# KD32F328CB register map
File version: 1.0
Registers are 32-bit, read-write, reset 0x0 unless marked. A register's access mark holds for its fields unless they carry their own. Offsets are from the block's base; [hi:lo] are bit positions; {n}, {i} and the like mark numbered series.

## Flash
Base 0x40022000
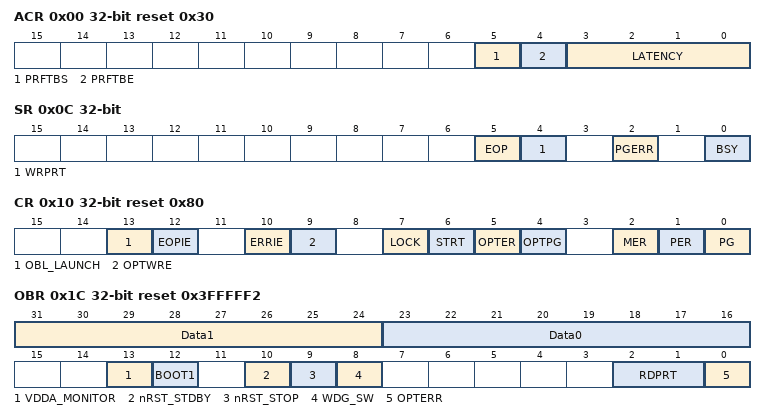
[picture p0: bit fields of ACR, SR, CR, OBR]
0x00 ACR access per field reset 0x30 — Flash access control register
  [5] PRFTBS ro, [4] PRFTBE rw, [3:0] LATENCY rw
0x04 KEYR wo — Flash key register
  [31:0] FKEYR — Flash Key
0x08 OPTKEYR wo — Flash option key register
  [31:0] OPTKEYR — Option byte key
0x0C SR access per field — Flash status register
  [5] EOP rw — End of operation
  [4] WRPRT rw — Write protection error
  [2] PGERR rw — Programming error
  [0] BSY ro — Busy
0x10 CR reset 0x80 — Flash control register
  [13] OBL_LAUNCH — Force option byte loading
  [12] EOPIE — End of operation interrupt enable
  [10] ERRIE — Error interrupt enable
  [9] OPTWRE — Option bytes write enable
  [7] LOCK
  [6] STRT — Start
  [5] OPTER — Option byte erase
  [4] OPTPG — Option byte programming
  [2] MER — Mass erase
  [1] PER — Page erase
  [0] PG — Programming
0x14 AR wo — Flash address register
  [31:0] FAR — Flash address
0x1C OBR ro reset 0x3FFFFF2 — Option byte register
  [31:24] Data1
  [23:16] Data0
  [13] VDDA_MONITOR
  [12] BOOT1
  [10] nRST_STDBY
  [9] nRST_STOP
  [8] WDG_SW
  [2:1] RDPRT — Level protection status
  [0] OPTERR — Option byte error
0x20 WRPR ro reset 0xFFFFFFFF — Write protection register
  [31:0] WRP — Write protect

## OP — operational support
Base 0x40010030
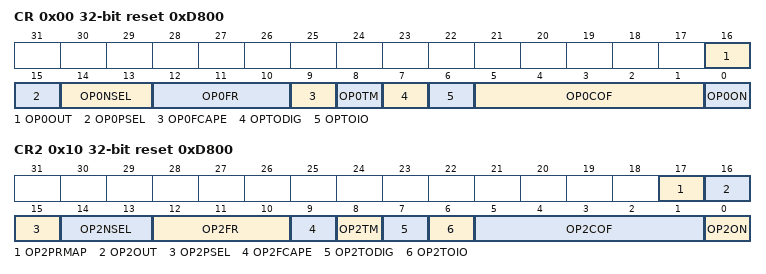
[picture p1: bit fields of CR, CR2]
0x00 CR reset 0xD800
  [16] OP0OUT — Revision Identifier
  [15] OP0PSEL — Revision Identifier
  [14:13] OP0NSEL — Revision Identifier
  [12:10] OP0FR — Revision Identifier
  [9] OP0FCAPE — Revision Identifier
  [8] OP0TM — Revision Identifier
  [7] OPTODIG — Revision Identifier
  [6] OPTOIO — Revision Identifier
  [5:1] OP0COF — Division Identifier
  [0] OP0ON — Device Identifier
0x10 CR2 reset 0xD800
  [17] OP2PRMAP — Revision Identifier
  [16] OP2OUT — Revision Identifier
  [15] OP2PSEL — Revision Identifier
  [14:13] OP2NSEL — Revision Identifier
  [12:10] OP2FR — Revision Identifier
  [9] OP2FCAPE — Revision Identifier
  [8] OP2TM — Revision Identifier
  [7] OP2TODIG — Revision Identifier
  [6] OP2TOIO — Revision Identifier
  [5:1] OP2COF — Division Identifier
  [0] OP2ON — Device Identifier

## DEBUG — Debug support
Base 0x40015800
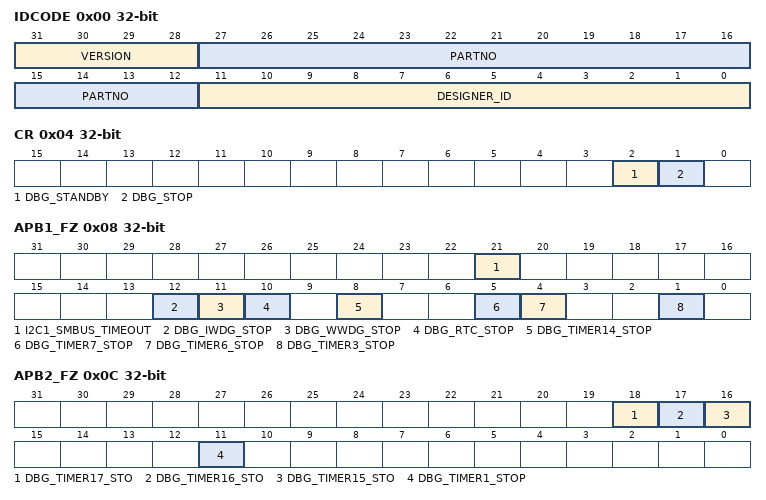
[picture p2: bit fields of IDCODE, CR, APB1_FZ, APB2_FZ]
0x00 IDCODE ro — MCU Device ID Code Register
  [31:28] VERSION — Revision Identifier
  [27:12] PARTNO — Division Identifier
  [11:0] DESIGNER_ID — Device Identifier
0x04 CR — Debug MCU Configuration Register
  [2] DBG_STANDBY — Debug Standby Mode
  [1] DBG_STOP — Debug Stop Mode
0x08 APB1_FZ — APB1 Freeze Register
  [21] I2C1_SMBUS_TIMEOUT — SMBUS timeout mode stopped when Core is halted
  [12] DBG_IWDG_STOP — Debug Independent Wachdog stopped when Core is halted
  [11] DBG_WWDG_STOP — Debug Window Wachdog stopped when Core is halted
  [10] DBG_RTC_STOP — Debug RTC stopped when Core is halted
  [8] DBG_TIMER14_STOP — Debug Timer 14 stopped when Core is halted
  [5] DBG_TIMER7_STOP — Debug Timer 7 stopped when Core is halted
  [4] DBG_TIMER6_STOP — Debug Timer 6 stopped when Core is halted
  [1] DBG_TIMER3_STOP — Debug Timer 3 stopped when Core is halted
0x0C APB2_FZ — APB2 Freeze Register
  [18] DBG_TIMER17_STO — Debug Timer 17 stopped when Core is halted
  [17] DBG_TIMER16_STO — Debug Timer 16 stopped when Core is halted
  [16] DBG_TIMER15_STO — Debug Timer 15 stopped when Core is halted
  [11] DBG_TIMER1_STOP — Debug Timer 1 stopped when Core is halted

## LEB — LEB and FLT support
Base 0x4000FC00
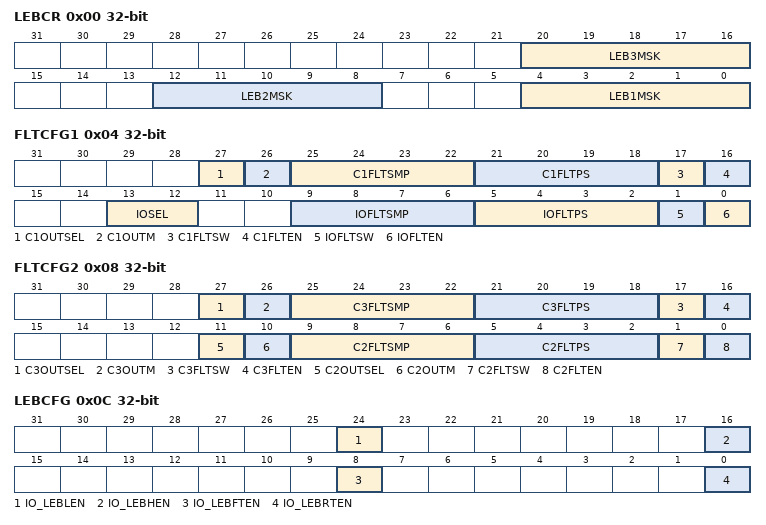
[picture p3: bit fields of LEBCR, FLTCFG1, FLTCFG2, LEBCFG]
0x00 LEBCR
  [20:16] LEB3MSK — LEB3MSK Identifier
  [12:8] LEB2MSK — LEB2MSK Identifier
  [4:0] LEB1MSK — LEB1MSK Identifier
0x04 FLTCFG1
  [27] C1OUTSEL — C1OUTSEL Identifier
  [26] C1OUTM — C1OUTM Identifier
  [25:22] C1FLTSMP — C1FLTSMP Identifier
  [21:18] C1FLTPS — C1FLTPS Identifier
  [17] C1FLTSW — C1FLTSW Identifier
  [16] C1FLTEN — C1FLTEN Identifier
  [13:12] IOSEL — IOSEL Identifier
  [9:6] IOFLTSMP — IOFLTSMP Identifier
  [5:2] IOFLTPS — IOFLTPS Identifier
  [1] IOFLTSW — IOFLTSW Identifier
  [0] IOFLTEN — IOFLTEN Identifier
0x08 FLTCFG2
  [27] C3OUTSEL — C3OUTSEL Identifier
  [26] C3OUTM — C3OUTM Identifier
  [25:22] C3FLTSMP — C3FLTSMP Identifier
  [21:18] C3FLTPS — C3FLTPS Identifier
  [17] C3FLTSW — C3FLTSW Identifier
  [16] C3FLTEN — C3FLTEN Identifier
  [11] C2OUTSEL — C2OUTSEL Identifier
  [10] C2OUTM — C2OUTM Identifier
  [9:6] C2FLTSMP — C2FLTSMP Identifier
  [5:2] C2FLTPS — C2FLTPS Identifier
  [1] C2FLTSW — C2FLTSW Identifier
  [0] C2FLTEN — C2FLTEN Identifier
0x0C LEBCFG
  [24] IO_LEBLEN — IO_LEBLEN Identifier
  [16] IO_LEBHEN — IO_LEBHEN Identifier
  [8] IO_LEBFTEN — IO_LEBFTEN Identifier
  [0] IO_LEBRTEN — IO_LEBRTEN Identifier
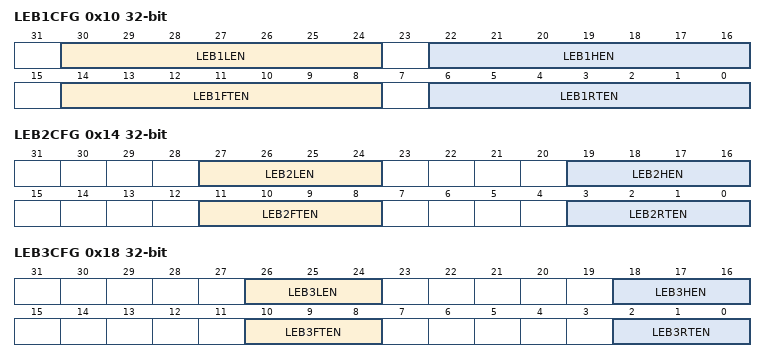
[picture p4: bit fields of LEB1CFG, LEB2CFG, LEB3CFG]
0x10 LEB1CFG
  [30:24] LEB1LEN — LEB1LEN Identifier
  [22:16] LEB1HEN — LEB1HEN Identifier
  [14:8] LEB1FTEN — LEB1FTEN Identifier
  [6:0] LEB1RTEN — LEB1RTEN Identifier
0x14 LEB2CFG
  [27:24] LEB2LEN — LEB2LEN Identifier
  [19:16] LEB2HEN — LEB2HEN Identifier
  [11:8] LEB2FTEN — LEB2FTEN Identifier
  [3:0] LEB2RTEN — LEB2RTEN Identifier
0x18 LEB3CFG
  [26:24] LEB3LEN — LEB3LEN Identifier
  [18:16] LEB3HEN — LEB3HEN Identifier
  [10:8] LEB3FTEN — LEB3FTEN Identifier
  [2:0] LEB3RTEN — LEB3RTEN Identifier
{0x18+4i} LEB{i}PR (i=1..3)
  [9:0] LEB{i}PR — LEB{i}PR Identifier

## DIV — DIV support
Base 0x40010080
0x00 DIV_DID
  [30:0] DID — Device Identifier
0x04 DIV_DIS
  [15:0] DIS — Device Identifier
0x08 DIV_QUO ro
  [30:0] QUO — Device Identifier
0x0C DIV_REM ro
  [15:0] REM — Device Identifier
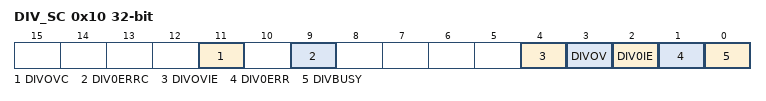
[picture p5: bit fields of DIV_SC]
0x10 DIV_SC access per field
  [11] DIVOVC ro — Device Identifier
  [9] DIV0ERRC ro — Device Identifier
  [4] DIVOVIE rw — Device Identifier
  [3] DIVOV ro — Device Identifier
  [2] DIV0IE rw — Device Identifier
  [1] DIV0ERR ro — Device Identifier
  [0] DIVBUSY ro — Device Identifier
